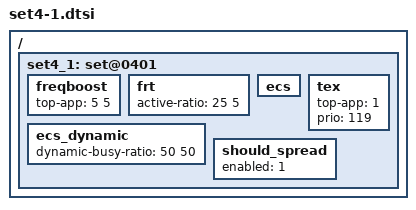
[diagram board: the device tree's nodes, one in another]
/ {
	/* balance mode - touch boost */
	set4_1: set@0401{
		freqboost {
			top-app = <5 5>;
		};

		frt {	   			/* LIT BIG */
			active-ratio 		= < 25   5>;
		};

		ecs { };

		ecs_dynamic {
			dynamic-busy-ratio = <50 50>;
		};

		tex {
			top-app = <1>;
			prio = <119>;
		};

		should_spread {
			enabled = <1>;
		};
	};
};
